AUTOSAR XML (schema 00052)
package /katech/AdaptiveApplicationSwComponentTypes
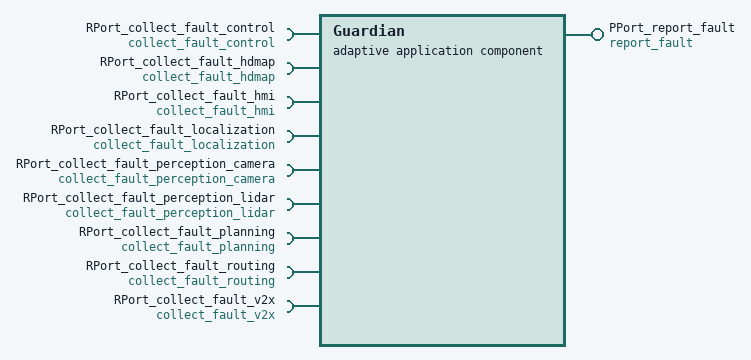
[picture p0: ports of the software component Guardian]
  adaptive application sw component type Guardian
    provide port PPort_report_fault: provided-interface=report_fault
    9 x require port:
      RPort_collect_fault_control: required-interface=collect_fault_control
      RPort_collect_fault_hdmap: required-interface=collect_fault_hdmap
      RPort_collect_fault_hmi: required-interface=collect_fault_hmi
      RPort_collect_fault_localization: required-interface=collect_fault_localization
      RPort_collect_fault_perception_camera: required-interface=collect_fault_perception_camera
      RPort_collect_fault_perception_lidar: required-interface=collect_fault_perception_lidar
      RPort_collect_fault_planning: required-interface=collect_fault_planning
      RPort_collect_fault_routing: required-interface=collect_fault_routing
      RPort_collect_fault_v2x: required-interface=collect_fault_v2x
package /katech/Executables
  executable Guardian: category=APPLICATION_LEVEL, minimum-timer-granularity=1000
    root sw component prototype Guardian: application-type=Guardian
